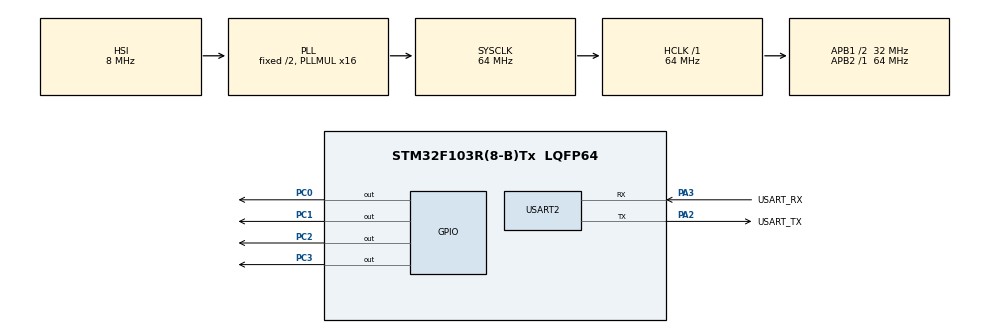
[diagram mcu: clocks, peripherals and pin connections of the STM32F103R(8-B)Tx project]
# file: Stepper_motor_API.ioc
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Mcu.Family=STM32F1
PC15-OSC32_OUT.Mode=LSE-External-Oscillator
PA2.GPIO_PuPd=GPIO_NOPULL
PD1-OSC_OUT.Mode=HSE-External-Clock-Source
PA14.GPIO_Label=TCK
PA3.GPIO_PuPd=GPIO_NOPULL
PC2.Signal=GPIO_Output
PA2.GPIO_Speed=GPIO_SPEED_FREQ_LOW
NVIC.TIM1_UP_IRQn=true\:0\:0\:false\:false\:true\:true\:true
PD0-OSC_IN.Signal=RCC_OSC_IN
PC0.Signal=GPIO_Output
RCC.APB1CLKDivider=RCC_HCLK_DIV2
PC14-OSC32_IN.Signal=RCC_OSC32_IN
PA3.GPIO_Speed=GPIO_SPEED_FREQ_LOW
RCC.SYSCLKSource=RCC_SYSCLKSOURCE_PLLCLK
ProjectManager.StackSize=0x400
PD1-OSC_OUT.Signal=RCC_OSC_OUT
PA13.Signal=SYS_JTMS-SWDIO
PA3.Mode=Asynchronous
TIM1.Prescaler=799
ProjectManager.TargetToolchain=SW4STM32
PA3.GPIO_Mode=GPIO_MODE_AF_PP
RCC.HCLKFreq_Value=64000000
RCC.APB2TimFreq_Value=64000000
PC3.Signal=GPIO_Output
RCC.USBFreq_Value=64000000
PC15-OSC32_OUT.Signal=RCC_OSC32_OUT
RCC.AHBFreq_Value=64000000
PD0-OSC_IN.Mode=HSE-External-Clock-Source
board=NUCLEO-F103RB
RCC.RTCClockSelection=RCC_RTCCLKSOURCE_LSE
RCC.PLLMUL=RCC_PLL_MUL16
RCC.APB2Freq_Value=64000000
PC14-OSC32_IN.Mode=LSE-External-Oscillator
PA14.Mode=Serial_Wire
PA13.Mode=Serial_Wire
Mcu.Name=STM32F103R(8-B)Tx
VP_TIM1_VS_ClockSourceINT.Mode=Internal
PA2.Signal=USART2_TX
PA13.GPIO_Label=TMS
PB3.Signal=SYS_JTDO-TRACESWO
RCC.SYSCLKFreq_VALUE=64000000
Mcu.Package=LQFP64
USART2.VirtualMode=VM_ASYNC
PA2.GPIO_Label=USART_TX
PA14.Signal=SYS_JTCK-SWCLK
NVIC.TIM1_BRK_IRQn=true\:0\:0\:false\:false\:true\:true\:true
ProjectManager.HeapSize=0x200
NVIC.PriorityGroup=NVIC_PRIORITYGROUP_4
RCC.APB1TimFreq_Value=64000000
PA2.Mode=Asynchronous
TIM1.Period=9
RCC.APB1Freq_Value=32000000
PC1.Signal=GPIO_Output
PA3.GPIO_Label=USART_RX
PA3.Signal=USART2_RX
PA2.GPIO_Mode=GPIO_MODE_AF_PP
PB3.GPIO_Label=SWO

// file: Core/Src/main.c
/* USER CODE BEGIN Header */
/**
  ******************************************************************************
  * @file           : main.c
  * @brief          : Main program body
  ******************************************************************************
  * @attention
  *
  * <h2><center>&copy; Copyright (c) 2020 STMicroelectronics.
  * All rights reserved.</center></h2>
  *
  * This software component is licensed by ST under BSD 3-Clause license,
  * the "License"; You may not use this file except in compliance with the
  * License. You may obtain a copy of the License at:
  *                        opensource.org/licenses/BSD-3-Clause
  *
  ******************************************************************************
  */
/* USER CODE END Header */
#include "main.h"

/* USER CODE BEGIN Includes */
#include "STEP_MOTOR_28BYJ-48-5V_NUCLEO-64_STMF103.h"
/* USER CODE END Includes */

TIM_HandleTypeDef htim1;

UART_HandleTypeDef huart2;

void SystemClock_Config(void);
static void MX_GPIO_Init(void);
static void MX_TIM1_Init(void);
static void MX_USART2_UART_Init(void);

int main(void)
{

  /* MCU Configuration--------------------------------------------------------*/

  /* Reset of all peripherals, Initializes the Flash interface and the Systick. */
  HAL_Init();

  /* Configure the system clock */
  SystemClock_Config();

  /* Initialize all configured peripherals */
  MX_GPIO_Init();
  MX_TIM1_Init();
  MX_USART2_UART_Init();
  /* USER CODE BEGIN 2 */
  // Set the pins to drive the stepper motor phases
  set_pins(GPIOC, GPIO_PIN_0, GPIO_PIN_1, GPIO_PIN_2, GPIO_PIN_3);
  // set the mode as half step
  set_step_mode(HALF_STEP);
  /* USER CODE END 2 */

  /* Infinite loop */
  /* USER CODE BEGIN WHILE */
  while (1)
  {
	  // turns the motor 40 steps in clockwise direction by 10 steps per second
	  turn_steps(40, 10, CLOCKWISE);
	  // stop the motor with full torque
	  stop(TORQUE);
	  // wait 500 milliseconds
	  HAL_delay(500);
	  // turns the motor infinitely in counterclockwise direction with 5 steps per second
	  turn_infinite(5, COUNTERCLOCKWISE);
	  // wait 500 milliseconds
	  HAL_delay(500);
    /* USER CODE END WHILE */

  }
}

void SystemClock_Config(void)
{
  RCC_OscInitTypeDef RCC_OscInitStruct = {0};
  RCC_ClkInitTypeDef RCC_ClkInitStruct = {0};

  /** Initializes the RCC Oscillators according to the specified parameters
  * in the RCC_OscInitTypeDef structure.
  */
  RCC_OscInitStruct.OscillatorType = RCC_OSCILLATORTYPE_HSI;
  RCC_OscInitStruct.HSIState = RCC_HSI_ON;
  RCC_OscInitStruct.HSICalibrationValue = RCC_HSICALIBRATION_DEFAULT;
  RCC_OscInitStruct.PLL.PLLState = RCC_PLL_ON;
  RCC_OscInitStruct.PLL.PLLSource = RCC_PLLSOURCE_HSI_DIV2;
  RCC_OscInitStruct.PLL.PLLMUL = RCC_PLL_MUL16;
  if (HAL_RCC_OscConfig(&RCC_OscInitStruct) != HAL_OK)
  {
    Error_Handler();
  }
  /** Initializes the CPU, AHB and APB buses clocks
  */
  RCC_ClkInitStruct.ClockType = RCC_CLOCKTYPE_HCLK|RCC_CLOCKTYPE_SYSCLK
                              |RCC_CLOCKTYPE_PCLK1|RCC_CLOCKTYPE_PCLK2;
  RCC_ClkInitStruct.SYSCLKSource = RCC_SYSCLKSOURCE_PLLCLK;
  RCC_ClkInitStruct.AHBCLKDivider = RCC_SYSCLK_DIV1;
  RCC_ClkInitStruct.APB1CLKDivider = RCC_HCLK_DIV2;
  RCC_ClkInitStruct.APB2CLKDivider = RCC_HCLK_DIV1;

  if (HAL_RCC_ClockConfig(&RCC_ClkInitStruct, FLASH_LATENCY_2) != HAL_OK)
  {
    Error_Handler();
  }
}

static void MX_TIM1_Init(void)
{

  TIM_ClockConfigTypeDef sClockSourceConfig = {0};
  TIM_MasterConfigTypeDef sMasterConfig = {0};

  htim1.Instance = TIM1;
  htim1.Init.Prescaler = 799;
  htim1.Init.CounterMode = TIM_COUNTERMODE_UP;
  htim1.Init.Period = 9;
  htim1.Init.ClockDivision = TIM_CLOCKDIVISION_DIV1;
  htim1.Init.RepetitionCounter = 0;
  htim1.Init.AutoReloadPreload = TIM_AUTORELOAD_PRELOAD_DISABLE;
  if (HAL_TIM_Base_Init(&htim1) != HAL_OK)
  {
    Error_Handler();
  }
  sClockSourceConfig.ClockSource = TIM_CLOCKSOURCE_INTERNAL;
  if (HAL_TIM_ConfigClockSource(&htim1, &sClockSourceConfig) != HAL_OK)
  {
    Error_Handler();
  }
  sMasterConfig.MasterOutputTrigger = TIM_TRGO_RESET;
  sMasterConfig.MasterSlaveMode = TIM_MASTERSLAVEMODE_DISABLE;
  if (HAL_TIMEx_MasterConfigSynchronization(&htim1, &sMasterConfig) != HAL_OK)
  {
    Error_Handler();
  }

}

static void MX_USART2_UART_Init(void)
{

  huart2.Instance = USART2;
  huart2.Init.BaudRate = 115200;
  huart2.Init.WordLength = UART_WORDLENGTH_8B;
  huart2.Init.StopBits = UART_STOPBITS_1;
  huart2.Init.Parity = UART_PARITY_NONE;
  huart2.Init.Mode = UART_MODE_TX_RX;
  huart2.Init.HwFlowCtl = UART_HWCONTROL_NONE;
  huart2.Init.OverSampling = UART_OVERSAMPLING_16;
  if (HAL_UART_Init(&huart2) != HAL_OK)
  {
    Error_Handler();
  }

}

static void MX_GPIO_Init(void)
{
  GPIO_InitTypeDef GPIO_InitStruct = {0};

  /* GPIO Ports Clock Enable */
  __HAL_RCC_GPIOC_CLK_ENABLE();
  __HAL_RCC_GPIOD_CLK_ENABLE();
  __HAL_RCC_GPIOA_CLK_ENABLE();
  __HAL_RCC_GPIOB_CLK_ENABLE();

  /*Configure GPIO pin Output Level */
  HAL_GPIO_WritePin(GPIOC, GPIO_PIN_0|GPIO_PIN_1|GPIO_PIN_2|GPIO_PIN_3, GPIO_PIN_RESET);

  /*Configure GPIO pins : PC0 PC1 PC2 PC3 */
  GPIO_InitStruct.Pin = GPIO_PIN_0|GPIO_PIN_1|GPIO_PIN_2|GPIO_PIN_3;
  GPIO_InitStruct.Mode = GPIO_MODE_OUTPUT_PP;
  GPIO_InitStruct.Pull = GPIO_NOPULL;
  GPIO_InitStruct.Speed = GPIO_SPEED_FREQ_LOW;
  HAL_GPIO_Init(GPIOC, &GPIO_InitStruct);

}

void Error_Handler(void)
{
}

/************************ (C) COPYRIGHT STMicroelectronics *****END OF FILE****/
